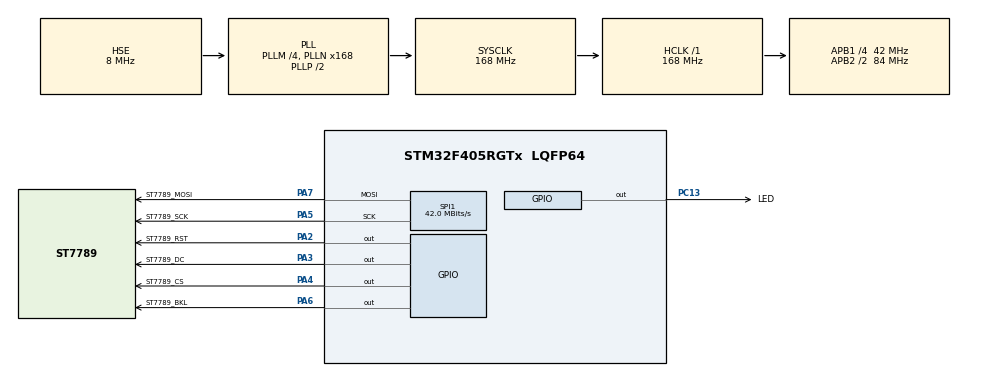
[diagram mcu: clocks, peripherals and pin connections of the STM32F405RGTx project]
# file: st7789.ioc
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Mcu.Family=STM32F4
Mcu.Name=STM32F405RGTx
Mcu.Package=LQFP64
NVIC.PriorityGroup=NVIC_PRIORITYGROUP_4
NVIC.TIM4_IRQn=true\:0\:0\:false\:false\:true\:true\:true
PA13.Mode=Serial_Wire
PA13.Signal=SYS_JTMS-SWDIO
PA14.Mode=Serial_Wire
PA14.Signal=SYS_JTCK-SWCLK
PA2.GPIO_Label=ST7789_RST
PA2.GPIO_PuPd=GPIO_PULLUP
PA2.GPIO_Speed=GPIO_SPEED_FREQ_HIGH
PA2.Signal=GPIO_Output
PA3.GPIO_Label=ST7789_DC
PA3.GPIO_PuPd=GPIO_PULLUP
PA3.GPIO_Speed=GPIO_SPEED_FREQ_HIGH
PA3.Signal=GPIO_Output
PA4.GPIO_Label=ST7789_CS
PA4.GPIO_PuPd=GPIO_PULLUP
PA4.GPIO_Speed=GPIO_SPEED_FREQ_HIGH
PA4.Signal=GPIO_Output
PA5.GPIO_Label=ST7789_SCK
PA5.GPIO_Speed=GPIO_SPEED_FREQ_VERY_HIGH
PA5.Mode=TX_Only_Simplex_Unidirect_Master
PA5.Signal=SPI1_SCK
PA6.GPIO_Label=ST7789_BKL
PA6.Signal=GPIO_Output
PA7.GPIO_Label=ST7789_MOSI
PA7.Mode=TX_Only_Simplex_Unidirect_Master
PA7.Signal=SPI1_MOSI
PC13-ANTI_TAMP.GPIO_Label=LED
PC13-ANTI_TAMP.GPIO_ModeDefaultOutputPP=GPIO_MODE_OUTPUT_OD
PC13-ANTI_TAMP.Signal=GPIO_Output
PH0-OSC_IN.Mode=HSE-External-Oscillator
PH0-OSC_IN.Signal=RCC_OSC_IN
PH1-OSC_OUT.Mode=HSE-External-Oscillator
PH1-OSC_OUT.Signal=RCC_OSC_OUT
ProjectManager.HeapSize=0x200
ProjectManager.StackSize=0x400
ProjectManager.TargetToolchain=STM32CubeIDE
RCC.48MHZClocksFreq_Value=84000000
RCC.AHBFreq_Value=168000000
RCC.APB1CLKDivider=RCC_HCLK_DIV4
RCC.APB1Freq_Value=42000000
RCC.APB1TimFreq_Value=84000000
RCC.APB2CLKDivider=RCC_HCLK_DIV2
RCC.APB2Freq_Value=84000000
RCC.APB2TimFreq_Value=168000000
RCC.CortexFreq_Value=168000000
RCC.HCLKFreq_Value=168000000
RCC.HSE_VALUE=8000000
RCC.HSI_VALUE=16000000
RCC.LSE_VALUE=32768
RCC.PLLM=4
RCC.PLLN=168
RCC.PLLSourceVirtual=RCC_PLLSOURCE_HSE
RCC.SYSCLKFreq_VALUE=168000000
RCC.SYSCLKSource=RCC_SYSCLKSOURCE_PLLCLK
RCC.VCOOutputFreq_Value=336000000
SPI1.BaudRatePrescaler=SPI_BAUDRATEPRESCALER_2
SPI1.CLKPolarity=SPI_POLARITY_HIGH
SPI1.CalculateBaudRate=42.0 MBits/s
SPI1.Direction=SPI_DIRECTION_2LINES
SPI1.Mode=SPI_MODE_MASTER
SPI1.VirtualType=VM_MASTER
TIM4.AutoReloadPreload=TIM_AUTORELOAD_PRELOAD_ENABLE
TIM4.Period=4999
TIM4.Prescaler=8399
TIM4.TIM_MasterOutputTrigger=TIM_TRGO_UPDATE
VP_TIM4_VS_ClockSourceINT.Mode=Internal
board=custom

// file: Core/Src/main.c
/* USER CODE BEGIN Header */
/**
  ******************************************************************************
  * @file           : main.c
  * @brief          : Main program body
  ******************************************************************************
  * @attention
  *
  * <h2><center>&copy; Copyright (c) 2020 STMicroelectronics.
  * All rights reserved.</center></h2>
  *
  * This software component is licensed by ST under BSD 3-Clause license,
  * the "License"; You may not use this file except in compliance with the
  * License. You may obtain a copy of the License at:
  *                        opensource.org/licenses/BSD-3-Clause
  *
  ******************************************************************************
  */
/* USER CODE END Header */
#include "main.h"

/* USER CODE BEGIN Includes */
#include "st7789.h"
/* USER CODE END Includes */

SPI_HandleTypeDef hspi1;

TIM_HandleTypeDef htim4;

void SystemClock_Config(void);
static void MX_GPIO_Init(void);
static void MX_SPI1_Init(void);
static void MX_TIM4_Init(void);

/* USER CODE BEGIN 0 */

void HAL_TIM_PeriodElapsedCallback(TIM_HandleTypeDef *htim) {
      if (htim->Instance == TIM4) {
              HAL_GPIO_TogglePin(LED_GPIO_Port, LED_Pin);
      }
}

/* USER CODE END 0 */

int main(void)
{

  /* MCU Configuration--------------------------------------------------------*/

  /* Reset of all peripherals, Initializes the Flash interface and the Systick. */
  HAL_Init();

  /* Configure the system clock */
  SystemClock_Config();

  /* Initialize all configured peripherals */
  MX_GPIO_Init();
  MX_SPI1_Init();
  MX_TIM4_Init();
  /* USER CODE BEGIN 2 */

  HAL_TIM_Base_Start_IT(&htim4);

  ST7789_Init(&hspi1);

  /* USER CODE END 2 */

  /* Infinite loop */
  /* USER CODE BEGIN WHILE */
  while (1)
  {

	ST7789_Test();

    /* USER CODE END WHILE */

  }
}

void SystemClock_Config(void)
{
  RCC_OscInitTypeDef RCC_OscInitStruct = {0};
  RCC_ClkInitTypeDef RCC_ClkInitStruct = {0};

  /** Configure the main internal regulator output voltage
  */
  __HAL_RCC_PWR_CLK_ENABLE();
  __HAL_PWR_VOLTAGESCALING_CONFIG(PWR_REGULATOR_VOLTAGE_SCALE1);
  /** Initializes the RCC Oscillators according to the specified parameters
  * in the RCC_OscInitTypeDef structure.
  */
  RCC_OscInitStruct.OscillatorType = RCC_OSCILLATORTYPE_HSE;
  RCC_OscInitStruct.HSEState = RCC_HSE_ON;
  RCC_OscInitStruct.PLL.PLLState = RCC_PLL_ON;
  RCC_OscInitStruct.PLL.PLLSource = RCC_PLLSOURCE_HSE;
  RCC_OscInitStruct.PLL.PLLM = 4;
  RCC_OscInitStruct.PLL.PLLN = 168;
  RCC_OscInitStruct.PLL.PLLP = RCC_PLLP_DIV2;
  RCC_OscInitStruct.PLL.PLLQ = 4;
  if (HAL_RCC_OscConfig(&RCC_OscInitStruct) != HAL_OK)
  {
    Error_Handler();
  }
  /** Initializes the CPU, AHB and APB buses clocks
  */
  RCC_ClkInitStruct.ClockType = RCC_CLOCKTYPE_HCLK|RCC_CLOCKTYPE_SYSCLK
                              |RCC_CLOCKTYPE_PCLK1|RCC_CLOCKTYPE_PCLK2;
  RCC_ClkInitStruct.SYSCLKSource = RCC_SYSCLKSOURCE_PLLCLK;
  RCC_ClkInitStruct.AHBCLKDivider = RCC_SYSCLK_DIV1;
  RCC_ClkInitStruct.APB1CLKDivider = RCC_HCLK_DIV4;
  RCC_ClkInitStruct.APB2CLKDivider = RCC_HCLK_DIV2;

  if (HAL_RCC_ClockConfig(&RCC_ClkInitStruct, FLASH_LATENCY_5) != HAL_OK)
  {
    Error_Handler();
  }
}

static void MX_SPI1_Init(void)
{

  /* SPI1 parameter configuration*/
  hspi1.Instance = SPI1;
  hspi1.Init.Mode = SPI_MODE_MASTER;
  hspi1.Init.Direction = SPI_DIRECTION_2LINES;
  hspi1.Init.DataSize = SPI_DATASIZE_8BIT;
  hspi1.Init.CLKPolarity = SPI_POLARITY_HIGH;
  hspi1.Init.CLKPhase = SPI_PHASE_1EDGE;
  hspi1.Init.NSS = SPI_NSS_SOFT;
  hspi1.Init.BaudRatePrescaler = SPI_BAUDRATEPRESCALER_2;
  hspi1.Init.FirstBit = SPI_FIRSTBIT_MSB;
  hspi1.Init.TIMode = SPI_TIMODE_DISABLE;
  hspi1.Init.CRCCalculation = SPI_CRCCALCULATION_DISABLE;
  hspi1.Init.CRCPolynomial = 10;
  if (HAL_SPI_Init(&hspi1) != HAL_OK)
  {
    Error_Handler();
  }

}

static void MX_TIM4_Init(void)
{

  TIM_ClockConfigTypeDef sClockSourceConfig = {0};
  TIM_MasterConfigTypeDef sMasterConfig = {0};

  htim4.Instance = TIM4;
  htim4.Init.Prescaler = 8399;
  htim4.Init.CounterMode = TIM_COUNTERMODE_UP;
  htim4.Init.Period = 4999;
  htim4.Init.ClockDivision = TIM_CLOCKDIVISION_DIV1;
  htim4.Init.AutoReloadPreload = TIM_AUTORELOAD_PRELOAD_ENABLE;
  if (HAL_TIM_Base_Init(&htim4) != HAL_OK)
  {
    Error_Handler();
  }
  sClockSourceConfig.ClockSource = TIM_CLOCKSOURCE_INTERNAL;
  if (HAL_TIM_ConfigClockSource(&htim4, &sClockSourceConfig) != HAL_OK)
  {
    Error_Handler();
  }
  sMasterConfig.MasterOutputTrigger = TIM_TRGO_UPDATE;
  sMasterConfig.MasterSlaveMode = TIM_MASTERSLAVEMODE_DISABLE;
  if (HAL_TIMEx_MasterConfigSynchronization(&htim4, &sMasterConfig) != HAL_OK)
  {
    Error_Handler();
  }

}

static void MX_GPIO_Init(void)
{
  GPIO_InitTypeDef GPIO_InitStruct = {0};

  /* GPIO Ports Clock Enable */
  __HAL_RCC_GPIOC_CLK_ENABLE();
  __HAL_RCC_GPIOH_CLK_ENABLE();
  __HAL_RCC_GPIOA_CLK_ENABLE();

  /*Configure GPIO pin Output Level */
  HAL_GPIO_WritePin(LED_GPIO_Port, LED_Pin, GPIO_PIN_RESET);

  /*Configure GPIO pin Output Level */
  HAL_GPIO_WritePin(GPIOA, ST7789_RST_Pin|ST7789_DC_Pin|ST7789_CS_Pin|ST7789_BKL_Pin, GPIO_PIN_RESET);

  /*Configure GPIO pin : LED_Pin */
  GPIO_InitStruct.Pin = LED_Pin;
  GPIO_InitStruct.Mode = GPIO_MODE_OUTPUT_OD;
  GPIO_InitStruct.Pull = GPIO_NOPULL;
  GPIO_InitStruct.Speed = GPIO_SPEED_FREQ_LOW;
  HAL_GPIO_Init(LED_GPIO_Port, &GPIO_InitStruct);

  /*Configure GPIO pins : ST7789_RST_Pin ST7789_DC_Pin ST7789_CS_Pin */
  GPIO_InitStruct.Pin = ST7789_RST_Pin|ST7789_DC_Pin|ST7789_CS_Pin;
  GPIO_InitStruct.Mode = GPIO_MODE_OUTPUT_PP;
  GPIO_InitStruct.Pull = GPIO_PULLUP;
  GPIO_InitStruct.Speed = GPIO_SPEED_FREQ_HIGH;
  HAL_GPIO_Init(GPIOA, &GPIO_InitStruct);

  /*Configure GPIO pin : ST7789_BKL_Pin */
  GPIO_InitStruct.Pin = ST7789_BKL_Pin;
  GPIO_InitStruct.Mode = GPIO_MODE_OUTPUT_PP;
  GPIO_InitStruct.Pull = GPIO_NOPULL;
  GPIO_InitStruct.Speed = GPIO_SPEED_FREQ_LOW;
  HAL_GPIO_Init(ST7789_BKL_GPIO_Port, &GPIO_InitStruct);

}

void Error_Handler(void)
{
}

/************************ (C) COPYRIGHT STMicroelectronics *****END OF FILE****/
